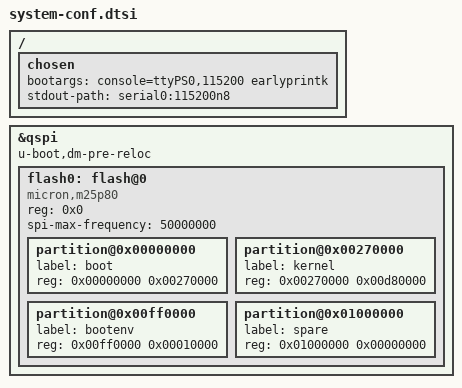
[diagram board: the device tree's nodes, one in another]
/*
 * CAUTION: This file is automatically generated by PetaLinux SDK.
 * DO NOT modify this file
 */


/ {
	chosen {
		bootargs = "console=ttyPS0,115200 earlyprintk";
		stdout-path = "serial0:115200n8";
	};
};

&qspi {
	u-boot,dm-pre-reloc;
	#address-cells = <1>;
	#size-cells = <0>;
	flash0: flash@0 {
		compatible = "micron,m25p80";
		reg = <0x0>;
		#address-cells = <1>;
		#size-cells = <1>;
		spi-max-frequency = <50000000>;
		partition@0x00000000 {
			label = "boot";
			reg = <0x00000000 0x00270000>;
		};
		partition@0x00270000 {
			label = "kernel";
			reg = <0x00270000 0x00d80000>;
		};
		partition@0x00ff0000 {
			label = "bootenv";
			reg = <0x00ff0000 0x00010000>;
		};
		partition@0x01000000 {
			label = "spare";
			reg = <0x01000000 0x00000000>;
		};
	};
};

